# PIC32MK1024MCF064 device description
Architecture: MIPS; Family: PIC32MK; Series: PIC32MK
Registers are 32-bit, read-write, no defined reset value unless marked. A register's access mark holds for its fields unless they carry their own. Offsets are from the block's base; [hi:lo] are bit positions; {n}, {i} and the like mark numbered series; 'fields as' and 'values as' point back to an identical list.

## FUSECONFIG
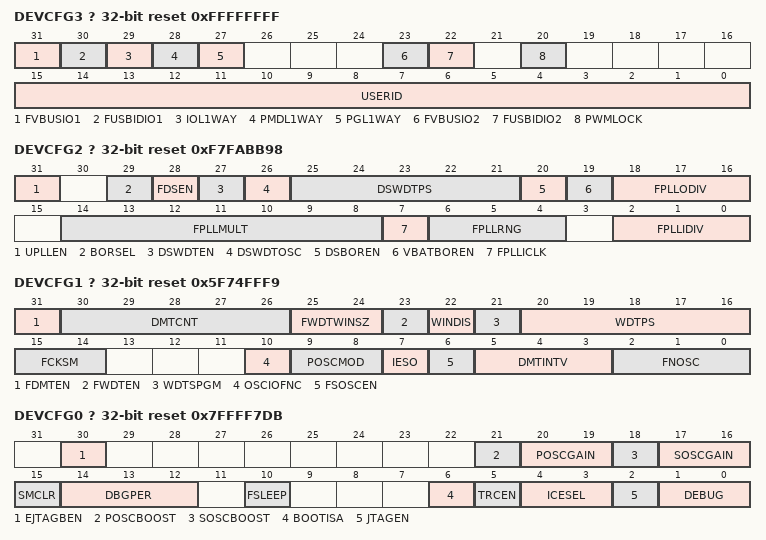
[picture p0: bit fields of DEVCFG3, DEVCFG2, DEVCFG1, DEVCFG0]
? DEVCFG3 size not given access not given reset 0xFFFFFFFF — Device Configuration Word 3
  [31] FVBUSIO1 — USB1 VBUSON Selection bit
    1=ON (VBUSON pin is controlled by the USB1 module); 0=OFF (VBUSON pin is controlled by the port function)
  [30] FUSBIDIO1 — USB1 USBID Selection bit
    1=ON (USBID pin is controlled by the USB module); 0=OFF (USBID pin is controlled by the port function)
  [29] IOL1WAY — Peripheral Pin Select Configuration bit
    1=ON (Allow only one reconfiguration); 0=OFF (Allow multiple reconfigurations)
  [28] PMDL1WAY — Peripheral Module Disable Configuration bit
    values as IOL1WAY
  [27] PGL1WAY — Permission Group Lock One Way Configuration bit
    values as IOL1WAY
  [23] FVBUSIO2 — USB2 VBUSON Selection bit
    1=ON (VBUSON pin is controlled by the USB2 module); 0=OFF (VBUSON pin is controlled by the port function)
  [22] FUSBIDIO2 — USB2 USBID Selection bit
    1=ON (USBID pin is controlled by the USB2 module); 0=OFF (USBID pin is controlled by the port function)
  [20] PWMLOCK — PWM Write Access Select bit
    1=OFF (Write accesses to the PWM IOCONx register are not locked or protected); 0=ON (Write accesses to the PWM IOCONx register must use the PWMKEY unlock procedure)
  [15:0] USERID
    ?=User ID
? DEVCFG2 size not given access not given reset 0xF7FABB98 — Device Configuration Word 2
  [31] UPLLEN — USB PLL Enable bit
    1=OFF (USB PLL is disabled); 0=ON (USB PLL is enabled)
  [29] BORSEL — Brown-out Reset Select Trip Voltage bit
    1=HIGH (BOR trip voltage 2.1V (non-Op amp device operation)); 0=LOW (BOR trip voltage 2.8V (Op amp device operation))
  [28] FDSEN — Deep Sleep Enable bit
    0=OFF (DS bit (DSCON bit 15) is disabled); 1=ON (DS bit (DSCON bit 15) is enabled on a WAIT command)
  [27] DSWDTEN — Deep Sleep Watchdog Timer Enable bit
    0=OFF (Disable DSWDT during Deep Sleep); 1=ON (Enable DSWDT during Deep Sleep)
  [26] DSWDTOSC — Deep Sleep Watchdog Timer Reference Clock Select bit
    0=SOSC (Select SOSC as DSWDT Reference Clock); 1=LPRC (Select LPRC as DSWDT Reference clock)
  [25:21] DSWDTPS — Deep Sleep Watchdog Timer Postscale Select bits
    31=DSPS32 (1:236 (25.7 days)); 30=DSPS31 (1:235 (12.8 days)); 29=DSPS30 (1:234 (6.4 days)); 28=DSPS29 (1:233 (77.0 hours)); 27=DSPS28 (1:232 (38.5 hours)); 26=DSPS27 (1:231 (19.2 hours)); 25=DSPS26 (1:230 (9.6 hours)); 24=DSPS25 (1:229 (4.8 hours)); 23=DSPS24 (1:228 (2.4 hours)); 22=DSPS23 (1:227 (72.2 minutes)); 21=DSPS22 (1:226 (36.1 minutes)); 20=DSPS21 (1:225 (18.0 minutes)); 19=DSPS20 (1:224 (9.0 minutes)); 18=DSPS19 (1:223 (4.5 minutes)); 17=DSPS18 (1:222 (135.3 s)); 16=DSPS17 (1:221 (67.7 s)); 15=DSPS16 (1:220 (33.825 s)); 14=DSPS15 (1:219 (16.912 s)); 13=DSPS14 (1:218 (8.456 s)); 12=DSPS13 (1:217 (4.228 s)); 11=DSPS12 (1:65536 (2.114 s)); 10=DSPS11 (1:32768 (1.057 s)); 9=DSPS10 (1:16384 (528.5 ms)); 8=DSPS9 (1:8192 (264.3 ms)); 7=DSPS8 (1:4096 (132.1 ms)); 6=DSPS7 (1:2048 (66.1 ms)); 5=DSPS6 (1:1024 (33 ms)); 4=DSPS5 (1:512 (16.5 ms)); 3=DSPS4 (1:256 (8.3 ms)); 2=DSPS3 (1:128 (4.1 ms)); 1=DSPS2 (1:64 (2.1 ms)); 0=DSPS1 (1:32 (1 ms))
  [20] DSBOREN — Deep Sleep BOR Enable bit
    0=OFF (Disable ZPBOR during deep sleep); 1=ON (Enable ZPBOR during deep sleep)
  [19] VBATBOREN — VBAT BOR Enable bit
    0=OFF (Disable ZPBOR during VBAT Mode); 1=ON (Enable ZPBOR during VBAT Mode)
  [18:16] FPLLODIV — Default System PLL Output Divisor bits
    1=DIV_2 (PLL output divided by 2); 2=DIV_4 (PLL output divided by 4); 3=DIV_8 (PLL output divided by 8); 4=DIV_16 (PLL output divided by 16); 7=DIV_32 (PLL output divided by 32)
  [14:8] FPLLMULT — System PLL Feedback Divider bits
    {v}=MUL_{v+1} (Multiply by {v+1}) (v=0..127)
  [7] FPLLICLK — System PLL Input Clock Select bit
    1=PLL_FRC (FRC is selected as input to the System PLL); 0=PLL_POSC (POSC is selected as input to the System PLL)
  [6:4] FPLLRNG — System PLL Divided Input Clock Frequency Range bits
    0=RANGE_BYPASS (Bypass); 1=RANGE_5_10_MHZ (5-10 MHz); 2=RANGE_8_16_MHZ (8-16 MHz); 3=RANGE_13_26_MHZ (13-26 MHz); 4=RANGE_21_42_MHZ (21-42 MHz); 5=RANGE_34_64_MHZ (34-64 MHz)
  [2:0] FPLLIDIV — PLL Input Divider bits
    {v}=DIV_{v+1} (Divide by {v+1}) (v=0..7)
? DEVCFG1 size not given access not given reset 0x5F74FFF9 — Device Configuration Word 1
  [31] FDMTEN — Deadman Timer enable bit
    1=ON (Deadman Timer is enabled and cannot be disabled by software); 0=OFF (Deadman Timer is disabled and can be enabled by software)
  [30:26] DMTCNT — Deadman Timer Count Select bits
    0=DMT8 (2^8 (256)); 1=DMT9 (2^9 (512)); 2=DMT10 (2^10 (1024)); 3=DMT11 (2^11 (2048)); 4=DMT12 (2^12 (4096)); 5=DMT13 (2^13 (8192)); 6=DMT14 (2^14 (16384)); 7=DMT15 (2^15 (32768)); 8=DMT16 (2^16 (65536)); 9=DMT17 (2^17 (131072)); 10=DMT18 (2^18 (262144)); 11=DMT19 (2^19 (524288)); 12=DMT20 (2^20 (1048576)); 13=DMT21 (2^21 (2097152)); 14=DMT22 (2^22 (4194304)); 15=DMT23 (2^23 (8388608)); 16=DMT24 (2^24 (16777216)); 17=DMT25 (2^25 (33554432)); 18=DMT26 (2^26 (67108864)); 19=DMT27 (2^27 (134217728)); 20=DMT28 (2^28 (268435456)); 21=DMT29 (2^29 (536870912)); 22=DMT30 (2^30 (1073741824)); 23=DMT31 (2^31 (2147483648))
  [25:24] FWDTWINSZ — Watchdog Timer Window Size bits
    3=WINSZ_25 (Window size is 25%); 2=WINSZ_37 (Window size is 37.5%); 1=WINSZ_50 (Window size is 50%); 0=WINSZ_75 (Window size is 75%)
  [23] FWDTEN — Watchdog Timer Enable bit
    0=OFF (Watchdog Timer is not enabled; it can be enabled in software); 1=ON (Watchdog Timer is enabled and cannot be disabled by software)
  [22] WINDIS — Watchdog Timer Window Enable bit
    1=NORMAL (Watchdog Timer is in non-Window mode); 0=WINDOW (Watchdog Timer is in Window mode)
  [21] WDTSPGM — Watchdog Timer Stop During Flash Programming bit
    0=RUN (WDT runs during Flash programming); 1=STOP (WDT stops during Flash programming)
  [20:16] WDTPS — Watchdog Timer Postscale Select bits
    0=PS1 (1:1); 1=PS2 (1:2); 2=PS4 (1:4); 3=PS8 (1:8); 4=PS16 (1:16); 5=PS32 (1:32); 6=PS64 (1:64); 7=PS128 (1:128); 8=PS256 (1:256); 9=PS512 (1:512); 10=PS1024 (1:1024); 11=PS2048 (1:2048); 12=PS4096 (1:4096); 13=PS8192 (1:8192); 14=PS16384 (1:16384); 15=PS32768 (1:32768); 16=PS65536 (1:65536); 17=PS131072 (1:131072); 18=PS262144 (1:262144); 19=PS524288 (1:524288); 20=PS1048576 (1:1048576)
  [15:14] FCKSM — Clock Switching and Monitoring Selection Configuration bits
    0=CSDCMD (Software Clock switching is disabled and clock monitoring is disabled); 1=CSECMD (Software Clock switching is enabled and clock monitoring is disabled); 2=CSDCME (Software Clock switching is disabled and clock monitoring is enabled); 3=CSECME (Software Clock switching is enabled and clock monitoring is enabled)
  [10] OSCIOFNC — CLKO Enable Configuration bit
    1=OFF (CLKO output is disabled); 0=ON (CLKO output signal active on the OSCO pin)
  [9:8] POSCMOD — Primary Oscillator Configuration bits
    0=EC (EC mode is selected); 2=HS (HS Oscillator mode is selected); 3=OFF (POSC is disabled)
  [7] IESO — Internal External Switchover bit
    0=OFF (Internal External Switchover mode is disabled (Two-Speed Start-up is disabled)); 1=ON (Internal External Switchover mode is enabled (Two-Speed Start-up is enabled))
  [6] FSOSCEN — Secondary Oscillator Enable bit
    0=OFF (Disable SOSC); 1=ON (Enable SOSC)
  [5:3] DMTINTV — Deadman Timer Count Window Interval bits
    0=WIN_0 (Window/Interval value is zero); 1=WIN_1_2 (Window/Interval value is 1/2 counter value); 2=WIN_3_4 (Window/Interval value is 3/4 counter value); 3=WIN_7_8 (Window/Interval value is 7/8 counter value); 4=WIN_15_16 (Window/Interval value is 15/16 counter value); 5=WIN_31_32 (Window/Interval value is 31/32 counter value); 6=WIN_63_64 (Window/Interval value is 63/64 counter value); 7=WIN_127_128 (Window/Interval value is 127/128 counter value)
  [2:0] FNOSC — Oscillator Selection bits
    0=FRC (FRC divided by FRCDIV bits); 1=SPLL (System PLL (SPLL Module) (input clock and divider set by SPLLCON)); 2=POSC (Primary Osc (HS,EC)); 3=UPLL (USB PLL (UPLL Module) (input clock and divider set by UPLLCON)); 4=SOSC (Secondary Oscillator (SOSC)); 5=LPRC (Low Power RC Oscillator (LPRC))
? DEVCFG0 size not given access not given reset 0x7FFFF7DB — Device Configuration Word 0
  [30] EJTAGBEN — EJTAG Boot Enable bit
    0=REDUCED (Reduced EJTAG functionality); 1=NORMAL (Normal EJTAG functionality)
  [21] POSCBOOST — Primary Oscillator Boost bit
    1=ON (Boost the kick start of the oscillator); 0=OFF (Normal start of the oscillator)
  [20:19] POSCGAIN — Primary Crystal Oscillator Course Gain Control bits
    3=GAIN_LEVEL_3 (Gain level 3 (Highest)); 2=GAIN_LEVEL_2; 1=GAIN_LEVEL_1; 0=GAIN_LEVEL_0 (Gain level 0 (Lowest))
  [18] SOSCBOOST — Secondary Oscillator Kick Start Programmability bit
    values as POSCBOOST
  [17:16] SOSCGAIN — Secondary Oscillator Gain Control bits
    3=GAIN_2X (Gain level 3 (Highest)); 2=GAIN_1_5X (Gain level 2); 1=GAIN_0_5X (Gain level 1); 0=GAIN_1X (Gain level 0 (Lowest))
  [15] SMCLR — Soft Master Clear Enable bit
    0=MCLR_POR (MCLR pin generates a POR Reset); 1=MCLR_NORM (MCLR pin generates a normal system Reset)
  [14:12] DBGPER — Debug Mode CPU Access Permission
    4=ALLOW_PG2 (Allow CPU access to Permission Group 2 permission regions); 2=ALLOW_PG1 (Allow CPU access to Permission Group 1 permission regions); 1=ALLOW_PG0 (Allow CPU access to Permission Group 0 permission regions); 3=PG_1_0 (PG0: Allow PG1: Allow PG2: Deny); 5=PG_2_0 (PG0: Allow PG1: Deny PG2: Allow); 6=PG_2_1 (PG0: Deny PG1: Allow PG2: Allow); 7=PG_ALL (Allow CPU access to all permission regions); 0=PG_NONE (Deny CPU access to all permission regions)
  [10] FSLEEP — Flash Sleep Mode bit
    0=VREGS (Flash power down is controlled by the VREGS bit); 1=OFF (Flash is powered down when the device is in Sleep mode)
  [6] BOOTISA — Boot ISA Selection bit
    1=MIPS32 (Boot code and Exception code is MIPS32); 0=MICROMIPS (Boot code and Exception code is microMIPS)
  [5] TRCEN — Trace Enable bit
    1=ON (Trace features in the CPU are enabled); 0=OFF (Trace features in the CPU are disabled)
  [4:3] ICESEL — In-Circuit Emulator/Debugger Communication Channel Select bits
    3=ICS_PGx1 (Communicate on PGEC1/PGED1); 2=ICS_PGx2 (Communicate on PGEC2/PGED2); 1=ICS_PGx3 (Communicate on PGEC3/PGED3)
  [2] JTAGEN — JTAG Enable bit
    1=ON (JTAG Port Enabled); 0=OFF (JTAG Disabled)
  [1:0] DEBUG — Background Debugger Enable bits
    0=ON (Debugger is enabled); 3=OFF (Debugger is disabled)
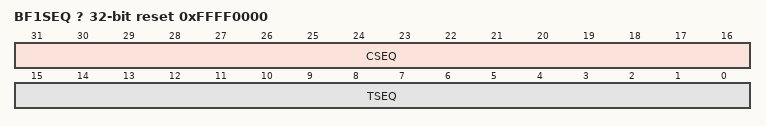
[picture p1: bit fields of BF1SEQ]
? BF1SEQ size not given access not given reset 0xFFFF0000 — BOOT FLASH 1 SEQUENCE WORD 0 REGISTER
  [31:16] CSEQ — Boot Flash Complement Sequence Number bits
  [15:0] TSEQ — Boot Flash True Sequence Number bits
Value list DEVCP0__CP: 0=ON (Protection is enabled); 0x10000000=OFF (Protection is disabled)
Value list SEQ3__TSEQ: ?=Boot Flash True Sequence Number
Value list SEQ3__CSEQ: ?=Boot Flash Complement Sequence Number

## Notices in the file
Copyright (c) 2017 Microchip Technology Inc.
SPDX-License-Identifier: Apache-2.0
Licensed under the Apache License, Version 2.0 (the "License");
you may not use this file except in compliance with the License.
You may obtain a copy of the License at
http://www.apache.org/licenses/LICENSE-2.0
Unless required by applicable law or agreed to in writing, software
distributed under the License is distributed on an "AS IS" BASIS,
WITHOUT WARRANTIES OR CONDITIONS OF ANY KIND, either express or implied.
See the License for the specific language governing permissions and
limitations under the License.
